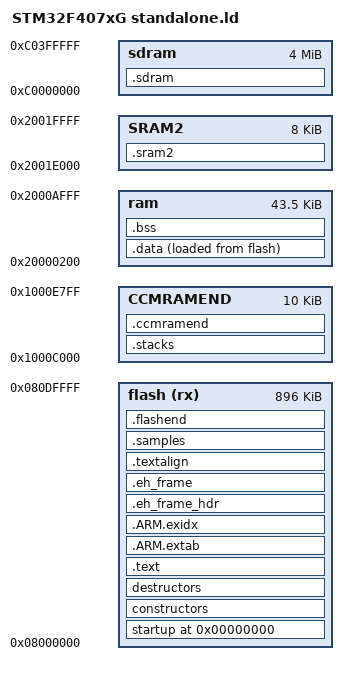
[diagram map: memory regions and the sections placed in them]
/**
 * Copyright (C) 2013, 2014, 2015 Johannes Taelman
 *
 * This file is part of Axoloti.
 *
 * Axoloti is free software: you can redistribute it and/or modify it under the
 * terms of the GNU General Public License as published by the Free Software
 * Foundation, either version 3 of the License, or (at your option) any later
 * version.
 *
 * Axoloti is distributed in the hope that it will be useful, but WITHOUT ANY
 * WARRANTY; without even the implied warranty of MERCHANTABILITY or FITNESS FOR
 * A PARTICULAR PURPOSE. See the GNU General Public License for more details.
 *
 * You should have received a copy of the GNU General Public License along with
 * Axoloti. If not, see <http://www.gnu.org/licenses/>.
 */

/*
 * ST32F407xG memory setup.
 */

__main_stack_size__     = 0x400;
__process_stack_size__  = 0x400;

MEMORY
{
    flash (rx): org = 0x08000000, len = 896k /* last 128kB for patch storage*/
    ram : org = 0x20000200, len = 0x0AE00 /* 44k - first 0x200 for vector table */
    SRAM2  : org = 0x2001E000, len = 0x00002000 /* second half (8kB) of SRAM2 for DMA*/      
    CCMRAMEND  : org = 0x1000C000, len = 10k /* for stacks */    
    sdram : org = 0xC0000000, len = 0x400000
}

__ram_start__           = ORIGIN(ram);
__ram_size__            = LENGTH(ram);
__ram_end__             = __ram_start__ + __ram_size__;

__sdram_start__ = ORIGIN(sdram);
__sdram_size__ = LENGTH(sdram);
__sdram_end__ = __sdram_start__ + __sdram_size__;

ENTRY(ResetHandler)

SECTIONS
{
    . = 0;
    _text = .;

    startup : ALIGN(16) SUBALIGN(16)
    {
        KEEP(*(vectors))
    } > flash

    constructors : ALIGN(4) SUBALIGN(4)
    {
        PROVIDE(__init_array_start = .);
        KEEP(*(SORT(.init_array.*)))
        KEEP(*(.init_array))
        PROVIDE(__init_array_end = .);
    } > flash

    destructors : ALIGN(4) SUBALIGN(4)
    {
        PROVIDE(__fini_array_start = .);
        KEEP(*(.fini_array))
        KEEP(*(SORT(.fini_array.*)))
        PROVIDE(__fini_array_end = .);
    } > flash

    .text : ALIGN(16) SUBALIGN(16)
    {
        *(.text.startup.*)
        *(.text)
        *(.text.*)
        *(.rodata)
        *(.rodata.*)
        *(.glue_7t)
        *(.glue_7)
        *(.gcc*)
    } > flash

    .ARM.extab :
    {
        *(.ARM.extab* .gnu.linkonce.armextab.*)
    } > flash

    .ARM.exidx : {
        PROVIDE(__exidx_start = .);
        *(.ARM.exidx* .gnu.linkonce.armexidx.*)
        PROVIDE(__exidx_end = .);
     } > flash

    .eh_frame_hdr :
    {
        *(.eh_frame_hdr)
    } > flash

    .eh_frame : ONLY_IF_RO
    {
        *(.eh_frame)
    } > flash
    
    .textalign : ONLY_IF_RO
    {
        . = ALIGN(8);
    } > flash

    .samples :  ONLY_IF_RO
    {
        . = ALIGN(8);
    } > flash


    _etext = .;
    _textdata = _etext;

    .stacks :
    {
        . = ALIGN(8);
        __main_stack_base__ = .;
        . += __main_stack_size__;
        . = ALIGN(8);
        __main_stack_end__ = .;
        __process_stack_base__ = .;
        __main_thread_stack_base__ = .;
        . += __process_stack_size__;
        . = ALIGN(8);
        __process_stack_end__ = .;
        __main_thread_stack_end__ = .;
    } > CCMRAMEND

    .data :
    {
        . = ALIGN(4);
        PROVIDE(_data = .);
        *(.data)
        . = ALIGN(4);
        *(.data.*)
        . = ALIGN(4);
        *(.ramtext)
        . = ALIGN(4);
        PROVIDE(_edata = .);
    } > ram AT > flash


    .flashend :
    {
        . = ALIGN(4);
        LONG(0x12345678)
        PROVIDE(_flash_end = .);
    } > flash

    .bss :
    {
        . = ALIGN(4);
        PROVIDE(_bss_start = .);
        *(.bss)
        . = ALIGN(4);
        *(.bss.*)
        . = ALIGN(4);
        *(COMMON)
        . = ALIGN(4);
        PROVIDE(_bss_end = .);
    } > ram
    
    .sram2 (NOLOAD): ALIGN(4) SUBALIGN(4) 
    {
        * (.sram2);
        * (.sram2.*);
    } > SRAM2    

    .ccmramend (NOLOAD): ALIGN(4) SUBALIGN(4)  
    {
        * (.ccmramend);
        * (.ccmramend.*);
    } > CCMRAMEND

    .sdram (NOLOAD) : ALIGN(4) SUBALIGN(4)
    {
        KEEP(*(.sdram))
        KEEP(*(.sdram.*))
    } > sdram
}

PROVIDE(end = .);
_end            = .;

__heap_base__   = _end;
__heap_end__    = __ram_end__;
